# RZT2ME register map
Vendor: Renesas Electronics Corporation; Series: RZT; File version: 1.00.00
CPU: other r0p0, little endian, MPU, no FPU, VTOR, 4 interrupt priority bits, 624 interrupts
Registers are 32-bit, read-write, reset 0x0 unless marked. A register's access mark holds for its fields unless they carry their own. Offsets are from the block's base; [hi:lo] are bit positions; {n}, {i} and the like mark numbered series; 'fields as' and 'values as' point back to an identical list.

## MTU — Multi-Function Timer Pulse Unit
Base 0x90001000
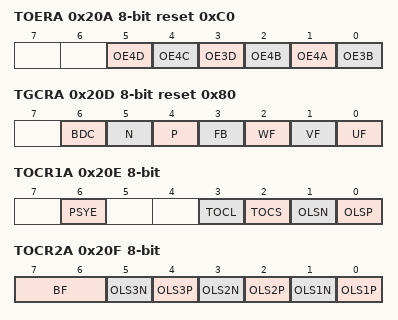
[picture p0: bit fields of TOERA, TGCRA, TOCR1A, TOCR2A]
0x20A TOERA 8-bit reset 0xC0 — Timer Output Master Enable Register A
  [all] fields
    0=MTU output is disabled (non-active level); 1=MTU output is enabled
  [5] OE4D — Master Enable MTIOC4D
  [4] OE4C — Master Enable MTIOC4C
  [3] OE3D — Master Enable MTIOC3D
  [2] OE4B — Master Enable MTIOC4B
  [1] OE4A — Master Enable MTIOC4A
  [0] OE3B — Master Enable MTIOC3B
0x20D TGCRA 8-bit reset 0x80 — Timer Gate Control Register A
  [6] BDC — Brushless DC Motor
    0=Ordinary output; 1=Functions of this register are made effective
  [5] N — Negative-Phase Output (N) Control
    0=Level output; 1=Reset-synchronized PWM or complementary PWM output
  [4] P — Positive-Phase Output (P) Control
    values as N
  [3] FB — External Feedback Signal Enable
    0=Output is switched by external input (input sources are TGRA, TGRB, and TGRC input capture signals in MTU0); 1=Output is switched by software (UF, VF, and WF settings)
  [2] WF — Output Phase Switch
  [1] VF — Output Phase Switch
  [0] UF — Output Phase Switch
0x20E TOCR1A 8-bit — Timer Output Control Register 1A
  [6] PSYE — PWM Synchronous Output Enable
    0=Toggle output is disabled; 1=Toggle output is enabled
  [3] TOCL — TOC Register Write Protection
    0=Write access to the TOCS, OLSN, and OLSP bits is enabled; 1=Write access to the TOCS, OLSN, and OLSP bits is disabled
  [2] TOCS — TOC Select
    0=TOCR1j setting is selected (j = A, B); 1=TOCR2j setting is selected (j = A, B)
  [1] OLSN — Output Level Select N
  [0] OLSP — Output Level Select P
0x20F TOCR2A 8-bit — Timer Output Control Register 2A
  [7:6] BF — TOLBR Buffer Transfer Timing Select
  [5] OLS3N — Output Level Select 3N
  [4] OLS3P — Output Level Select 3P
  [3] OLS2N — Output Level Select 2N
  [2] OLS2P — Output Level Select 2P
  [1] OLS1N — Output Level Select 1N
  [0] OLS1P — Output Level Select 1P
0x214 TCDRA 16-bit reset 0xFFFF — Timer Cycle Data Register A
0x216 TDDRA 16-bit reset 0xFFFF — Timer Dead Time Data Register A
0x220 TCNTSA 16-bit ro — Timer Subcounter A
0x222 TCBRA 16-bit reset 0xFFFF — Timer Cycle Buffer Register A
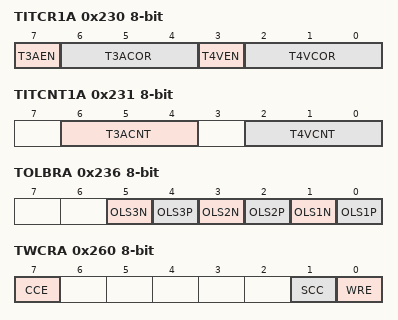
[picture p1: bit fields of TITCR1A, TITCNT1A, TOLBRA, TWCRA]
0x230 TITCR1A 8-bit — Timer Interrupt Skipping Set Register 1A
  [7] T3AEN — TGIA3 Interrupt Skipping Enable
    0=Disabled; 1=Enabled
  [6:4] T3ACOR — TGIA3 Interrupt Skipping Count Setting
    0=Does not skip TGIA3 interrupts; {v}=Sets the TGIA3 interrupt skipping count to {v} (v=1..7)
  [3] T4VEN — TCIV4 Interrupt Skipping Enable
    0=Disabled; 1=Enabled
  [2:0] T4VCOR — TCIV4 Interrupt Skipping Count Setting
    0=Does not skip TCIV4 interrupts; {v}=Sets the TCIV4 interrupt skipping count to {v} (v=1..7)
0x231 TITCNT1A 8-bit ro — Timer Interrupt Skipping Counter 1A
  [6:4] T3ACNT — TGIA3 Interrupt Counter
  [2:0] T4VCNT — TCIV4 Interrupt Counter
0x232 TBTERA 8-bit — Timer Buffer Transfer Set Register A
  [1:0] BTE — Buffer Transfer Disable and Interrupt Skipping Link Setting
0x234 TDERA 8-bit reset 0x1 — Timer Dead Time Enable Register A
  [0] TDER — Dead Time Enable
    0=No dead time is generated; 1=Dead time is generated
0x236 TOLBRA 8-bit — Timer Output Level Buffer Register A
  [5] OLS3N — Output Level Select 3N
  [4] OLS3P — Output Level Select 3P
  [3] OLS2N — Output Level Select 2N
  [2] OLS2P — Output Level Select 2P
  [1] OLS1N — Output Level Select 1N
  [0] OLS1P — Output Level Select 1P
0x23A TITMRA 8-bit — Timer Interrupt Skipping Mode Register A
  [0] TITM — Interrupt Skipping Function Select
    0=Selects interrupt skipping function 1 Setting the TITCR1A or TITCR1B register enables interrupt skipping function 1; 1=Selects interrupt skipping function 2 Setting the TITCR2A or TITCR2B register enables interrupt skipping function 2
0x23B TITCR2A 8-bit — Timer Interrupt Skipping Set Register 2A
  [2:0] TRG4COR — TRG4AN/TRG4BN Interrupt Skipping Count Setting
    0=Does not skip TRG4AN and TRG4BN interrupts; {v}=Sets the TRG4AN and TRG4BN interrupt skipping count to {v} (v=1..7)
0x23C TITCNT2A 8-bit ro — Timer Interrupt Skipping Counter 2A
  [2:0] TRG4CNT — TRG4AN/TRG4BN Interrupt Counter
0x260 TWCRA 8-bit — Timer Waveform Control Register A
  [7] CCE — Compare Match Clear Enable
    0=Counters are not cleared at MTU3.TGRA (MTU6.TGRA) compare match; 1=Counters are cleared at MTU3.TGRA (MTU6.TGRA) compare match
  [1] SCC — Synchronous Clearing Control (Only valid in TWCRB)
    0=Clearing of MTU6.TCNT and MTU7.TCNT in response to synchronous clearing for MTU0, MTU1, MTU2 to MTU6, and MTU7 is enabled; 1=Clearing of MTU6.TCNT and MTU7.TCNT in response to synchronous clearing for MTU0, MTU1, MTU2 to MTU6, and MTU7 is disabled
  [0] WRE — Waveform Retain Enable
    0=Initial values specified in TOCR1A and TOCR2A (TOCR1B and TOCR2B) are output; 1=Initial output is inhibited
0x270 TMDR2A 8-bit — Timer Mode Register 2A
  [0] DRS — Double Buffer Select
    0=Double buffer function is disabled; 1=Double buffer function is enabled
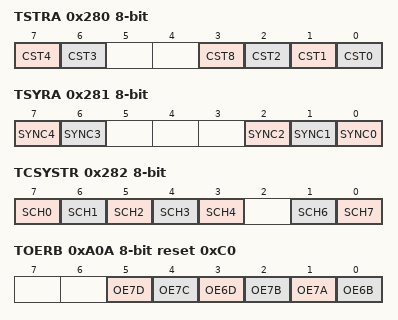
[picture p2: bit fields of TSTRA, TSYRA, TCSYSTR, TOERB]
0x280 TSTRA 8-bit — Timer Start Register A
  [7] CST4 — Counter Start 4
    0=MTU4.TCNT counting is stopped; 1=MTU4.TCNT performs count operation
  [6] CST3 — Counter Start 3
    0=MTU3.TCNT counting is stopped; 1=MTU3.TCNT performs count operation
  [3] CST8 — Counter Start 8
    0=MTU8.TCNT counting is stopped; 1=MTU8.TCNT performs count operation
  [2] CST2 — Counter Start 2
    0=MTU2.TCNT counting is stopped; 1=MTU2.TCNT performs count operation
  [1] CST1 — Counter Start 1
    0=MTU1.TCNT counting is stopped; 1=MTU1.TCNT performs count operation
  [0] CST0 — Counter Start 0
    0=MTU0.TCNT counting is stopped; 1=MTU0.TCNT performs count operation
0x281 TSYRA 8-bit — Timer Synchronous Register A
  [7] SYNC4 — Timer Synchronous Operation 4
    0=MTU4.TCNT operates independently (TCNT presetting/clearing is not related to other channels); 1=MTU4.TCNT performs synchronous operation (TCNT synchronous presetting/synchronous clearing is enabled)
  [6] SYNC3 — Timer Synchronous Operation 3
    0=MTU3.TCNT operates independently (TCNT presetting/clearing is not related to other channels); 1=MTU3.TCNT performs synchronous operation (TCNT synchronous presetting/synchronous clearing is enabled)
  [2] SYNC2 — Timer Synchronous Operation 2
    0=MTU2.TCNT operates independently (TCNT presetting/clearing is not related to other channels); 1=MTU2.TCNT performs synchronous operation (TCNT synchronous presetting/synchronous clearing is enabled)
  [1] SYNC1 — Timer Synchronous Operation 1
    0=MTU1.TCNT operates independently (TCNT presetting/clearing is not related to other channels); 1=MTU1.TCNT performs synchronous operation (TCNT synchronous presetting/synchronous clearing is enabled)
  [0] SYNC0 — Timer Synchronous Operation 0
    0=MTU0.TCNT operates independently (TCNT presetting/clearing is not related to other channels); 1=MTU0.TCNT performs synchronous operation (TCNT synchronous presetting/synchronous clearing is enabled)
0x282 TCSYSTR 8-bit — Timer Counter Synchronous Start Register
  [7-n] SCH{n} (n=0..4) — Synchronous Start {n}
    0=Does not specify synchronous start for MTU{n}.TCNT; 1=Specifies synchronous start for MTU{n}.TCNT
  [1] SCH6 — Synchronous Start 6
    0=Does not specify synchronous start for MTU6.TCNT; 1=Specifies synchronous start for MTU6.TCNT
  [0] SCH7 — Synchronous Start 7
    0=Does not specify synchronous start for MTU7.TCNT; 1=Specifies synchronous start for MTU7.TCNT
0x284 TRWERA 8-bit reset 0x1 — Timer Read/Write Enable Register A
  [0] RWE — Read/Write Enable
    0=Read/write access to the registers is disabled; 1=Read/write access to the registers is enabled
0xA0A TOERB 8-bit reset 0xC0 — Timer Output Master Enable Register B
  [all] fields
    values as the fields of TOERA
  [5] OE7D — Master Enable MTIOC7D
  [4] OE7C — Master Enable MTIOC7C
  [3] OE6D — Master Enable MTIOC6D
  [2] OE7B — Master Enable MTIOC7B
  [1] OE7A — Master Enable MTIOC7A
  [0] OE6B — Master Enable MTIOC6B
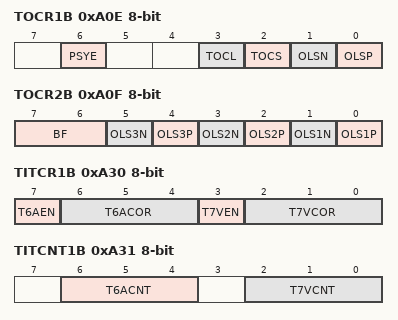
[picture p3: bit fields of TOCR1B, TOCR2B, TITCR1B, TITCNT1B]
0xA0E TOCR1B 8-bit — Timer Output Control Register 1B
  fields as TOCR1A
0xA0F TOCR2B 8-bit — Timer Output Control Register 2B
  fields as TOCR2A
0xA14 TCDRB 16-bit reset 0xFFFF — Timer Cycle Data Register B
0xA16 TDDRB 16-bit reset 0xFFFF — Timer Dead Time Data Register B
0xA20 TCNTSB 16-bit ro — Timer Subcounter B
0xA22 TCBRB 16-bit reset 0xFFFF — Timer Cycle Buffer Register B
0xA30 TITCR1B 8-bit — Timer Interrupt Skipping Set Register 1B
  [7] T6AEN — TGIA6 Interrupt Skipping Enable
    0=Disabled; 1=Enabled
  [6:4] T6ACOR — TGIA6 Interrupt Skipping Count Setting
    0=Does not skip TGIA6 interrupts; {v}=Sets the TGIA6 interrupt skipping count to {v} (v=1..7)
  [3] T7VEN — TCIV7 Interrupt Skipping Enable
    0=Disabled; 1=Enabled
  [2:0] T7VCOR — TCIV7 Interrupt Skipping Count Setting
    0=Does not skip TCIV7 interrupts; {v}=Sets the TCIV7 interrupt skipping count to {v} (v=1..7)
0xA31 TITCNT1B 8-bit ro — Timer Interrupt Skipping Counter 1B
  [6:4] T6ACNT — TGIA6 Interrupt Counter
  [2:0] T7VCNT — TCIV7 Interrupt Counter
0xA32 TBTERB 8-bit — Timer Buffer Transfer Set Register B
  fields as TBTERA
0xA34 TDERB 8-bit reset 0x1 — Timer Dead Time Enable Register B
  fields as TDERA
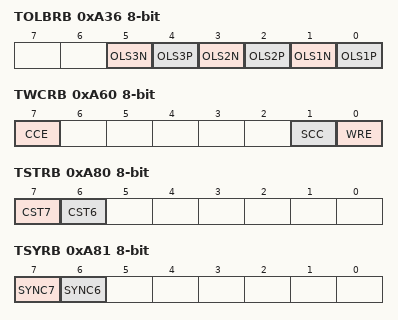
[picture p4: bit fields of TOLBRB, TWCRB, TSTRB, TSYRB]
0xA36 TOLBRB 8-bit — Timer Output Level Buffer Register B
  fields as TOLBRA
0xA3A TITMRB 8-bit — Timer Interrupt Skipping Mode Register B
  fields as TITMRA
0xA3B TITCR2B 8-bit — Timer Interrupt Skipping Set Register 2B
  [2:0] TRG7COR — TRG7AN/TRG7BN Interrupt Skipping Count Setting
    0=Does not skip TRG7AN and TRG7BN interrupts; {v}=Sets the TRG7AN and TRG7BN interrupt skipping count to {v} (v=1..7)
0xA3C TITCNT2B 8-bit ro — Timer Interrupt Skipping Counter 2B
  [2:0] TRG7CNT — TRG7AN/TRG7BN Interrupt Counter
0xA60 TWCRB 8-bit — Timer Waveform Control Register B
  fields as TWCRA
0xA70 TMDR2B 8-bit — Timer Mode Register 2B
  fields as TMDR2A
0xA80 TSTRB 8-bit — Timer Start Register B
  [7] CST7 — Counter Start 7
    0=MTU7.TCNT counting is stopped; 1=MTU7.TCNT performs count operation
  [6] CST6 — Counter Start 6
    0=MTU6.TCNT counting is stopped; 1=MTU6.TCNT performs count operation
0xA81 TSYRB 8-bit — Timer Synchronous Register B
  [7] SYNC7 — Timer Synchronous Operation 7
    0=MTU7.TCNT operates independently (TCNT presetting/clearing is not related to other channels); 1=MTU7.TCNT performs synchronous operation (TCNT synchronous presetting/synchronous clearing is enabled)
  [6] SYNC6 — Timer Synchronous Operation 6
    0=MTU6.TCNT operates independently (TCNT presetting/clearing is not related to other channels); 1=MTU6.TCNT performs synchronous operation (TCNT synchronous presetting/synchronous clearing is enabled)
0xA84 TRWERB 8-bit reset 0x1 — Timer Read/Write Enable Register B
  fields as TRWERA
